# K32W041AM register map
Vendor: nxp.com; File version: 1.0
CPU: CM4 r0p1, little endian, MPU, no FPU, VTOR, 3 interrupt priority bits
Registers are 32-bit, read-write, reset 0x0 unless marked. A register's access mark holds for its fields unless they carry their own. Offsets are from the block's base; [hi:lo] are bit positions.

## RNG — This is the description of component rng. It is an Universal Synchrnous/Asynchrnous Receiver/Transmitter with APB bus interface. More details will follow.
Base 0x4000D000
0x00 RANDOM_NUMBER ro
  [31:0] RAND_NUM — This register contains a random 32 bit number which is computed on demand, at each time it is read. Weak cryptographic post-processing is used to maximize throughput. The block will start computing before the first register access and so the reset value is not relevant.
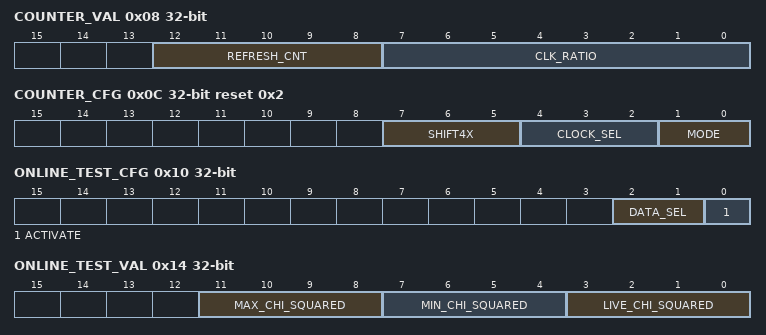
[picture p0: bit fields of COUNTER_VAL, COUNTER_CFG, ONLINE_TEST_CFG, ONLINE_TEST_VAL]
0x08 COUNTER_VAL ro — Counter values to show information about the random process
  [12:8] REFRESH_CNT — Incremented (till max possible value) each time COUNTER was updated since last reading to any *_NUMBER. This gives an indication on 'entropy refill'. Note that there is no linear accumulation of entropy: as implemented today, entropy refill will be about 4 bits each time 'refresh_cnt' reaches its maximum value. See user manual for further details on how to benefit from linear entropy accumulation using a specific procedure.
  [7:0] CLK_RATIO — Gives the ratio between the internal clocks frequencies and the register clock frequency for evaluation and certification purposes. Internal clock frequencies are half the incoming ones: COUNTER_VAL = round[ (intFreq/2)/regFreq*256*(1<<(4*shift4x)) ] MODULO 256 If shitf4x==0, intFreq ~= regFreq*COUNTER_VAL/256*2 Use clock_sel to select which clock you want to measure, in this range: 1..5
0x0C COUNTER_CFG reset 0x2 — Register linked to the comupting of statistics, not required for normal operation.
  [7:5] SHIFT4X — To be used to add precision to clock_ratio and determine 'entropy refill'. Supported range is 0..4 Used as well for ONLINE_TEST
  [4:2] CLOCK_SEL — Selects the internal clock on which to compute statistics. 1 is for first one, 2 for second one, . And 0 is for a XOR of results from all clocks
  [1:0] MODE — 00: disabled 01: update once. Will return to 00 once done 10: free running: updates countinuously 11: reserved
0x10 ONLINE_TEST_CFG — Configuration for the online test features
  [2:1] DATA_SEL — Selects source on which to apply online test: 00: LSB of COUNTER: raw data from one or all sources of entropy 01: MSB of COUNTER: raw data from one or all sources of entropy (do not use) 10: RANDOM_NUMBER 11: not valid 'activate' should be set to 'disabled' before changing this field
  [0] ACTIVATE — 0: disabled 1: activated Update rhythm for VAL depends on COUNTER_CFG if data_sel is set to COUNTER. Otherwise VAL is updated each time RANDOM_NUMBER is read
0x14 ONLINE_TEST_VAL ro — Online test results
  [11:8] MAX_CHI_SQUARED — Maximum value of LIVE_CHI_SQUARED since the last reset of this field. This field is reset when 'activate'=0
  [7:4] MIN_CHI_SQUARED — Minimum value of LIVE_CHI_SQUARED since the last reset of this field. This field is reset when 'activate'=0
  [3:0] LIVE_CHI_SQUARED — This value is updated as described in field 'activate'. This value is a statistic value that indicates the quality of entropy generation. Low value means good, high value means no good. If 'data_sel'<10, increase 'shift4x' till 'chi' is correct and poll 'refresh_cnt' before reading RANDOM_NUMBER.
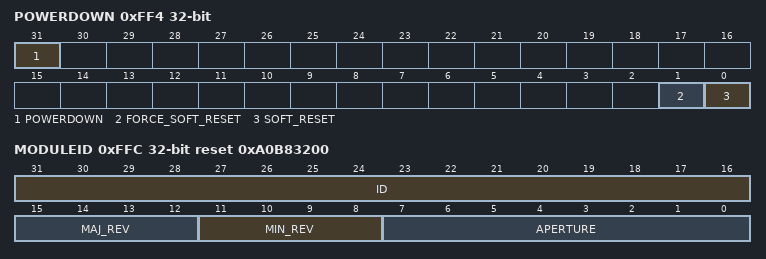
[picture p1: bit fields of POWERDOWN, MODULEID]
0xFF4 POWERDOWN — Powerdown mode and reset control, generally use of this register is not necessary
  [31] POWERDOWN — When set all accesses to standard registers are blocked
  [1] FORCE_SOFT_RESET — When used with softreset it forces CORE_RESETN to low on acknowledge from CORE
  [0] SOFT_RESET — Request softreset that will go low automaticaly after acknowledge from CORE
0xFFC MODULEID ro reset 0xA0B83200 — IP identifier
  [31:16] ID — Identifier. This is the unique identifier of the module
  [15:12] MAJ_REV — Major revision i.e. implies software modifications
  [11:8] MIN_REV — Minor revision i.e. with no software consequences
  [7:0] APERTURE — Aperture i.e. number minus 1 of consecutive packets 4 Kbytes reserved for this IP
